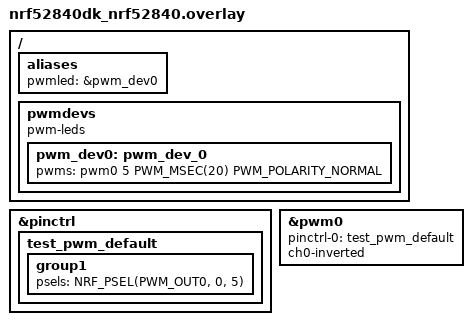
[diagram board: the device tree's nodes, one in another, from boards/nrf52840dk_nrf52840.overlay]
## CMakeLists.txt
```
cmake_minimum_required(VERSION 3.20.0)

set(BOARD nrf52840dk_nrf52840)

find_package(Zephyr REQUIRED HINTS $ENV{ZEPHYR_BASE})
project(basestation)

FILE(GLOB app_sources src/*.c)
target_sources(app PRIVATE ${app_sources})
```

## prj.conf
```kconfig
CONFIG_BT=y
# CONFIG_BT_DEBUG_LOG=y
CONFIG_BT_CENTRAL=y
CONFIG_BT_SMP=y
CONFIG_BT_GATT_CLIENT=y

CONFIG_STDOUT_CONSOLE=y
CONFIG_PRINTK=y
CONFIG_PWM=y
# CONFIG_LOG=y # Getting stack overflow with this var enabled
CONFIG_LOG_PRINTK=y
#CONFIG_LOG_MODE_IMMEDIATE=y
CONFIG_PWM_LOG_LEVEL_DBG=y

CONFIG_GPIO=y

CONFIG_THREAD_MONITOR=y
CONFIG_DEBUG=y
CONFIG_DEBUG_THREAD_INFO=y

CONFIG_USE_SEGGER_RTT=y
CONFIG_RTT_CONSOLE=y
CONFIG_UART_CONSOLE=n
```

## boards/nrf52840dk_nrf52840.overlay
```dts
#include <dt-bindings/pwm/pwm.h>
/ {
    aliases {
        pwmled = &pwm_dev0;
    };

    pwmdevs{
        compatible = "pwm-leds";
        pwm_dev0: pwm_dev_0{
        pwms = <&pwm0 5 PWM_MSEC(20) PWM_POLARITY_NORMAL>;
        };
    };
};

&pinctrl {
    test_pwm_default: test_pwm_default {
        group1 {
            psels = <NRF_PSEL(PWM_OUT0, 0, 5)>;
        };
    };
};

&pwm0 {
    status = "okay";
    pinctrl-0 = <&test_pwm_default>;
    //ch0-pin = <13>;
    ch0-inverted;
};
```

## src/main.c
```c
#include <zephyr/types.h>
#include <stddef.h>
#include <errno.h>
#include <zephyr.h>
#include <sys/printk.h>
#include "bluetooth.h"
#include "pwm-led.h"
#include <drivers/gpio.h>

#define MY_STACK_SIZE 				1000
#define BUTTON_DEBOUNCE_DELAY_MS 	100
#define THRESHOLD					20
#define ADJUSTMENT_STEP				2

/* Semaphore used to signal from button ISR to task */
K_SEM_DEFINE(button_sem, 0, 1);

//struct k_mutex state_mutex;
// Not sure we need a lock when there is only one writer and one reader
// It's only used by writer, so it doesn't really lock anyone out. So currently it does nothing.
K_MUTEX_DEFINE(state_mutex);

#define SW0_NODE	DT_ALIAS(sw0)
#define SW0			DT_GPIO_LABEL(SW0_NODE, gpios)
#define SW0_PIN		DT_GPIO_PIN(SW0_NODE, gpios)
#define SW0_FLAGS	(GPIO_INPUT | DT_GPIO_FLAGS(SW0_NODE, gpios))

/* Variables used for button debouncing */
static volatile uint32_t time, last_time;

typedef enum _state
{
	auto_adjust_off,
	auto_adjust_on
} state_t;

static volatile state_t basestation_state = auto_adjust_on;

typedef enum
{
	off				= 0,
	normal			= 150,
	simple_study 	= 250,
	intensive_study = 400
} brightness;

static volatile uint16_t reference_val = normal;
static volatile uint8_t adjustment_mode = 0;
K_MUTEX_DEFINE(mode_mutex);

uint16_t abs(uint16_t val) {
	if (val < 0) {
		return val * -1;
	}

	return val;
}

/* Compare measured value to reference value and increase/decrease brightness*/
void compare_to_reference(uint16_t measured_val)
{
	uint8_t new_adjustment_mode;

	printk("Reference: %d, measured: %d\n", reference_val, measured_val);
	if (abs(measured_val - reference_val) > THRESHOLD)
	{
		new_adjustment_mode = 1;
		if (measured_val > reference_val)
			decrease_brightness_by(ADJUSTMENT_STEP);
		else 
			increase_brightness_by(ADJUSTMENT_STEP);
	} else
	{
		new_adjustment_mode = 0;
	}

	// Send adjustment request only when it changes
	if (new_adjustment_mode != adjustment_mode) {
		adjustment_mode = new_adjustment_mode;
		if (adjustment_mode)
			request_adjustment(1);
		else
			request_adjustment(0);
	}
}

/* Change the mode, i.e. reference value, according to the received Bluetooth message */
void change_mode(uint16_t data)
{
	switch(data)
	{
		k_mutex_lock(&mode_mutex, K_FOREVER);

		case 0: 
			reference_val = off;
			break;
		case 1:
			reference_val = normal;
			break;
		case 2:
			reference_val = simple_study;
			break;
		case 3:
			reference_val = intensive_study;
			break;
		default:
			reference_val = reference_val;
			break;

		k_mutex_unlock(&mode_mutex);
	}
}

static void handle_bt_sensor_value(uint16_t data) 
{
	// printk("Received ambient light value %d lux\n", data);
	compare_to_reference(data);
}

static void handle_bt_button(uint16_t data) 
{
	printk("Received button value %d\n", data);
	change_mode(data);
}

void basestation_task(void) 
{
	pwm_led_init();

	int bt_okay = connect_bluetooth();
	if (!bt_okay) 
	{
		printk("Failed to connect to bluetooth");
		return;
	}
}

void button_pressed(const struct device *dev, struct gpio_callback *cb, uint32_t pins)
{
	/* Debounce the button */
	time = k_uptime_get_32();
	if (time < last_time + BUTTON_DEBOUNCE_DELAY_MS) 
	{
		last_time = time;
		return;
	}
	k_sem_give(&button_sem);
	time = last_time;
}

/* Structure to add callback to button pin */
/* Should not be on stack !!! */
static struct gpio_callback button_cb_data;

/* If button #0 was pressed, the basestation should be turned on/off */
void button_task()
{
	/* Set up button interrupt */
	const struct device *sw0;
	sw0 = device_get_binding(SW0);
	gpio_pin_configure(sw0, SW0_PIN, GPIO_INPUT | SW0_FLAGS);
	gpio_pin_interrupt_configure(sw0, SW0_PIN, GPIO_INT_EDGE_TO_ACTIVE);
	gpio_init_callback(&button_cb_data, button_pressed, BIT(SW0_PIN));
	gpio_add_callback(sw0, &button_cb_data);

	while(1)
	{
		k_sem_take(&button_sem, K_FOREVER);

		k_mutex_lock(&state_mutex, K_FOREVER);
		if(basestation_state == auto_adjust_off)
		{
			basestation_state = auto_adjust_on;
			printk("The auto adjustment has been turned on\n");
			connect_bluetooth();
		} else
		{
			basestation_state = auto_adjust_off;
			printk("The auto adjustment has been turned off\n");
			bt_conn_disconnect(default_conn, BT_HCI_ERR_REMOTE_POWER_OFF);
		}
		k_mutex_unlock(&state_mutex);
	}
}

K_THREAD_DEFINE(button_id, MY_STACK_SIZE, button_task, 
				NULL, NULL, NULL, 5, 0, 0);

K_THREAD_DEFINE(work_id, MY_STACK_SIZE, basestation_task,
				NULL, NULL, NULL, 5, 0, 0);
```

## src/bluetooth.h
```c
#include <bluetooth/bluetooth.h>
#include <bluetooth/hci.h>
#include <bluetooth/conn.h>
#include <bluetooth/uuid.h>
#include <bluetooth/gatt.h>
#include <sys/byteorder.h>

#define BT_CONTROLLER_SERVICE_UUID        BT_UUID_DECLARE_128(0xa3, 0x45, 0x36, 0xf1, 0xcc, 0x82, 0x4c, 0x80, 0xa4, 0x94, 0xd0, 0xc5, 0x1b, 0x5f, 0xb1, 0x1c)
#define BT_LIGHT_CHARACTERISTIC_UUID      BT_UUID_DECLARE_128(0xa3, 0x45, 0x36, 0xf2, 0xcc, 0x82, 0x4c, 0x80, 0xa4, 0x94, 0xd0, 0xc5, 0x1b, 0x5f, 0xb1, 0x1c)
#define BT_BUTTON_CHARACTERISTIC_UUID     BT_UUID_DECLARE_128(0xa3, 0x45, 0x36, 0xf3, 0xcc, 0x82, 0x4c, 0x80, 0xa4, 0x94, 0xd0, 0xc5, 0x1b, 0x5f, 0xb1, 0x1c)
#define BT_ADJUSTMENT_CHARACTERISTIC_UUID BT_UUID_DECLARE_128(0xa3, 0x45, 0x36, 0xf4, 0xcc, 0x82, 0x4c, 0x80, 0xa4, 0x94, 0xd0, 0xc5, 0x1b, 0x5f, 0xb1, 0x1c)

static void start_scan(void);
static void handle_bt_sensor_value(uint16_t data);
static void handle_bt_button(uint16_t data);

static struct bt_conn *default_conn;

static struct bt_uuid_128 uuid = BT_UUID_INIT_128(0);
static struct bt_gatt_discover_params discover_params;
static struct bt_gatt_subscribe_params subscribe_params_light;
static struct bt_gatt_subscribe_params subscribe_params_buttons;
static struct bt_gatt_write_params write_params_adjustment;

static uint8_t notify_func(struct bt_conn *conn, struct bt_gatt_subscribe_params *params, const void *data, uint16_t length) {
	if (!data) {
		printk("[UNSUBSCRIBED]\n");
		params->value_handle = 0U;
		return BT_GATT_ITER_STOP;
	}

	uint16_t value = ((uint16_t *)data)[0];
	if (params->value_handle == subscribe_params_light.value_handle) {
		handle_bt_sensor_value(value);
	} else if (params->value_handle == subscribe_params_buttons.value_handle) {
		handle_bt_button(value);
	}

	return BT_GATT_ITER_CONTINUE;
}

static uint8_t discover_func(struct bt_conn *conn, const struct bt_gatt_attr *attr, struct bt_gatt_discover_params *params) {
	int err;

	if (!attr) {
		printk("Discover complete\n");
		(void)memset(params, 0, sizeof(*params));
		return BT_GATT_ITER_STOP;
	}

	printk("Discovered attribute: %d (perm: %d)\n", bt_gatt_attr_value_handle(attr), attr->perm);
	if (bt_uuid_cmp(discover_params.uuid, BT_CONTROLLER_SERVICE_UUID) == 0) {
		printk("Discovering light value characteristic\n");
		memcpy(&uuid, BT_LIGHT_CHARACTERISTIC_UUID, sizeof(uuid));
		discover_params.uuid = &uuid.uuid;
		discover_params.start_handle = attr->handle + 1;
		discover_params.type = BT_GATT_DISCOVER_CHARACTERISTIC;

		err = bt_gatt_discover(conn, &discover_params);
		if (err) {
			printk("Discover failed (err %d)\n", err);
		}
	} else if (bt_uuid_cmp(discover_params.uuid, BT_LIGHT_CHARACTERISTIC_UUID) == 0) {
		printk("Discovering button characteristic\n");
		memcpy(&uuid, BT_BUTTON_CHARACTERISTIC_UUID, sizeof(uuid));
		discover_params.uuid = &uuid.uuid;
		discover_params.start_handle = attr->handle + 2;
		discover_params.type = BT_GATT_DISCOVER_CHARACTERISTIC;
		subscribe_params_light.value_handle = bt_gatt_attr_value_handle(attr);

		err = bt_gatt_discover(conn, &discover_params);
		if (err) {
			printk("Discover failed (err %d)\n", err);
		}
	} else if (bt_uuid_cmp(discover_params.uuid, BT_BUTTON_CHARACTERISTIC_UUID) == 0) {
		printk("Discovering adjustment characteristic\n");
		memcpy(&uuid, BT_ADJUSTMENT_CHARACTERISTIC_UUID, sizeof(uuid));
		discover_params.uuid = &uuid.uuid;
		discover_params.start_handle = attr->handle + 2;
		discover_params.type = BT_GATT_DISCOVER_CHARACTERISTIC;
		subscribe_params_buttons.value_handle = bt_gatt_attr_value_handle(attr);

		err = bt_gatt_discover(conn, &discover_params);
		if (err) {
			printk("Discover failed (err %d)\n", err);
		}
	} else if (bt_uuid_cmp(discover_params.uuid, BT_ADJUSTMENT_CHARACTERISTIC_UUID) == 0) {
		printk("Discovering CCC descriptor\n");
	 	memcpy(&uuid, BT_UUID_GATT_CCC, sizeof(uuid));
		discover_params.uuid = &uuid.uuid;
		discover_params.start_handle = attr->handle + 2;
		discover_params.type = BT_GATT_DISCOVER_DESCRIPTOR;
		write_params_adjustment.handle = bt_gatt_attr_value_handle(attr);

		err = bt_gatt_discover(conn, &discover_params);
		if (err) {
			printk("Discover failed (err %d)\n", err);
		}
	} else {
		subscribe_params_light.notify = notify_func;
		subscribe_params_light.value = BT_GATT_CCC_NOTIFY;
		subscribe_params_light.ccc_handle = attr->handle;
		subscribe_params_buttons.notify = notify_func;
		subscribe_params_buttons.value = BT_GATT_CCC_NOTIFY;
		subscribe_params_buttons.ccc_handle = attr->handle;

		printk("Subscribing to light...\n");
		err = bt_gatt_subscribe(conn, &subscribe_params_light);
		if (err && err != -EALREADY) {
			printk("Subscribe failed (err %d)\n", err);
		} else {
			printk("[SUBSCRIBED]\n");
		}

		printk("Subscribing to desired light...\n");
		err = bt_gatt_subscribe(conn, &subscribe_params_buttons);
		if (err && err != -EALREADY) {
			printk("Subscribe failed (err %d)\n", err);
		} else {
			printk("[SUBSCRIBED]\n");
		}
	}

	return BT_GATT_ITER_STOP;
}

static bool eir_found(struct bt_data *data, void *user_data)
{
	bt_addr_le_t *addr = user_data;
	int err;
	struct bt_le_conn_param *param;

	printk("[AD]: %u data_len %u\n", data->type, data->data_len);

	switch (data->type) {
	case BT_DATA_UUID128_SOME:
	case BT_DATA_UUID128_ALL:
		if (data->data_len % sizeof(uint16_t) != 0U) {
			printk("AD malformed\n");
			return true;
		}

		if (data->data_len == BT_UUID_SIZE_128) {
			if (bt_uuid_cmp(BT_UUID_DECLARE_128( // This is ugly
				data->data[0], data->data[1], data->data[2], data->data[3],
				data->data[4], data->data[5], data->data[6], data->data[7],
				data->data[8], data->data[9], data->data[10], data->data[11],
				data->data[12], data->data[13], data->data[14], data->data[15]
			), BT_CONTROLLER_SERVICE_UUID) == 0) {
				printk("Found controller service!\n");
				err = bt_le_scan_stop();
				if (err) {
					printk("Stop LE scan failed (err %d)\n", err);
					return true;
				}

				param = BT_LE_CONN_PARAM_DEFAULT;
				err = bt_conn_le_create(addr, BT_CONN_LE_CREATE_CONN,
							param, &default_conn);
				if (err) {
					printk("Create conn failed (err %d)\n", err);
					start_scan();
				}
			} else {
				printk("No match\n");
				return true;
			}

			return false;
		}
	}

	return true;
}

static void device_found(const bt_addr_le_t *addr, int8_t rssi, uint8_t type,
			 struct net_buf_simple *ad)
{
	char dev[BT_ADDR_LE_STR_LEN];

	bt_addr_le_to_str(addr, dev, sizeof(dev));
	printk("[DEVICE]: %s, AD evt type %u, AD data len %u, RSSI %i\n",
	       dev, type, ad->len, rssi);

	/* We're only interested in connectable events */
	if (type == BT_GAP_ADV_TYPE_ADV_IND ||
	    type == BT_GAP_ADV_TYPE_ADV_DIRECT_IND) {
		bt_data_parse(ad, eir_found, (void *)addr);
	}
}

static void start_scan(void)
{
	int err;

	/* Use active scanning and disable duplicate filtering to handle any
	 * devices that might update their advertising data at runtime. */
	struct bt_le_scan_param scan_param = {
		.type       = BT_LE_SCAN_TYPE_ACTIVE,
		.options    = BT_LE_SCAN_OPT_NONE,
		.interval   = BT_GAP_SCAN_FAST_INTERVAL,
		.window     = BT_GAP_SCAN_FAST_WINDOW,
	};

	err = bt_le_scan_start(&scan_param, device_found);
	if (err) {
		printk("Scanning failed to start (err %d)\n", err);
		return;
	}

	printk("Scanning successfully started\n");
}

static void connected(struct bt_conn *conn, uint8_t conn_err)
{
	char addr[BT_ADDR_LE_STR_LEN];
	int err;

	bt_addr_le_to_str(bt_conn_get_dst(conn), addr, sizeof(addr));

	if (conn_err) {
		printk("Failed to connect to %s (%u)\n", addr, conn_err);

		bt_conn_unref(default_conn);
		default_conn = NULL;

		start_scan();
		return;
	}

	printk("Connected: %s\n", addr);

	if (conn == default_conn) {
		// memcpy(&uuid, BT_UUID_HRS, sizeof(uuid));
		memcpy(&uuid, BT_CONTROLLER_SERVICE_UUID, sizeof(uuid));
		discover_params.uuid = &uuid.uuid;
		discover_params.func = discover_func;
		discover_params.start_handle = BT_ATT_FIRST_ATTRIBUTE_HANDLE;
		discover_params.end_handle = BT_ATT_LAST_ATTRIBUTE_HANDLE;
		discover_params.type = BT_GATT_DISCOVER_PRIMARY;

		printk("Discovering primary service\n");
		err = bt_gatt_discover(default_conn, &discover_params);
		if (err) {
			printk("Discover failed(err %d)\n", err);
			return;
		}
	}
}

static void disconnected(struct bt_conn *conn, uint8_t reason)
{
	char addr[BT_ADDR_LE_STR_LEN];

	bt_addr_le_to_str(bt_conn_get_dst(conn), addr, sizeof(addr));

	printk("Disconnected: %s (reason 0x%02x)\n", addr, reason);

	if (default_conn != conn) {
		return;
	}

	bt_conn_unref(default_conn);
	default_conn = NULL;

	// start_scan();
}

BT_CONN_CB_DEFINE(conn_callbacks) = {
	.connected = connected,
	.disconnected = disconnected,
};

/**
 * Function that initialized everything related with bluetooth
 */
static int connect_bluetooth() {
	int err = bt_enable(NULL);

	if (err && err != -EALREADY) {
		printk("Bluetooth init failed (err %d)\n", err);
        return 0;
	}

	printk("Bluetooth initialized\n");

	start_scan();

    return 1;
}

static void bt_gatt_write_func(struct bt_conn *conn, uint8_t err, struct bt_gatt_write_params *params) {
	// This might not be needed...
}

static void request_adjustment(uint8_t data) {
	write_params_adjustment.data = &data;
	write_params_adjustment.length = sizeof(data);
	write_params_adjustment.func = bt_gatt_write_func;
	write_params_adjustment.offset = 0;

	int ret = bt_gatt_write(default_conn, &write_params_adjustment);
	if (ret != 0) {
		printk("Failed to send adjustment request");
	}
}
```

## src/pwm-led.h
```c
#include <zephyr.h>
#include <sys/printk.h>
#include <device.h>
#include <drivers/pwm.h>

#define PWM_LED0_NODE	DT_ALIAS(pwmled)

#if DT_NODE_HAS_STATUS(PWM_LED0_NODE, okay)
#define PWM_CTLR	DT_PWMS_CTLR(PWM_LED0_NODE)
#define PWM_CHANNEL	DT_PWMS_CHANNEL(PWM_LED0_NODE)
#define PWM_FLAGS	DT_PWMS_FLAGS(PWM_LED0_NODE)
#else
#error "Unsupported board: pwm-led0 devicetree alias is not defined"
#define PWM_CTLR	DT_INVALID_NODE
#define PWM_CHANNEL	0
#define PWM_FLAGS	0
#endif

#define MIN_PERIOD_USEC	(USEC_PER_SEC / 128U)
#define MAX_PERIOD_USEC	USEC_PER_SEC

static const struct device *pwm;
static uint32_t max_period;
static uint32_t period;
static uint8_t duty_cycle;

static void pwm_led_init(void);
static void increase_brightness_by(uint8_t duty);
static void decrease_brightness_by(uint8_t duty);
static void set_brightness(uint8_t duty_cyle);

static void pwm_led_init()
{
    pwm = DEVICE_DT_GET(PWM_CTLR);
	if (!device_is_ready(pwm)) 
    {
		printk("Error: PWM device %s is not ready\n", pwm->name);
		return;
	}

    //Calibrate
    printk("Calibrating for channel %d...\n", PWM_CHANNEL);
	max_period = MAX_PERIOD_USEC;
	while (pwm_pin_set_usec(pwm, PWM_CHANNEL,
				max_period, max_period / 2U, PWM_FLAGS)) 
    {
		max_period /= 2U;
		if (max_period < (4U * MIN_PERIOD_USEC)) 
        {
			printk("Error: PWM device "
			       "does not support a period at least %u\n",
			       4U * MIN_PERIOD_USEC);
			return;
		}
	}

	printk("Done calibrating; maximum/minimum periods %u/%u usec\n",
	       max_period, MIN_PERIOD_USEC);

	period = MIN_PERIOD_USEC;

	duty_cycle = 50;
	
	set_brightness(duty_cycle);
}

static void decrease_brightness_by(uint8_t duty)
{
    
    if(duty < duty_cycle)
    {
        duty_cycle -= duty;
    } else
    {
        duty_cycle = 1;
    }

    int ret = pwm_pin_set_usec(pwm, PWM_CHANNEL,
				       period, (uint32_t ) period*duty_cycle/100, PWM_FLAGS);
		if (ret) 
        {
			printk("Error %d: failed to set pulse width\n", ret);
			return;
		}
}

static void increase_brightness_by(uint8_t duty)
{
    
    if(duty_cycle + duty < 100)
    {
        duty_cycle += duty;
    } else
    {
        duty_cycle = 99;
    }

    int ret = pwm_pin_set_usec(pwm, PWM_CHANNEL,
				       period, (uint32_t ) period*duty_cycle/100, PWM_FLAGS);
		if (ret) 
        {
			printk("Error %d: failed to set pulse width\n", ret);
			return;
		}
}

static void set_brightness(uint8_t duty_cycle)
{
    
    if(duty_cycle > 100)
    {
        printk("Failed to set duty cycle\n");
    } else
    {
        duty_cycle = 100-duty_cycle;
    }

    int ret = pwm_pin_set_usec(pwm, PWM_CHANNEL,
				       period, (uint32_t ) period*duty_cycle/100, PWM_FLAGS);
		if (ret) 
        {
			printk("Error %d: failed to set pulse width\n", ret);
			return;
		}
}
```
